# BlueNRG_LP register map
File version: 1.0
CPU: CM0+ r0p0, little endian, no MPU, no FPU, 2 interrupt priority bits
Registers are 32-bit, read-write, reset 0x0 unless marked. A register's access mark holds for its fields unless they carry their own. Offsets are from the block's base; [hi:lo] are bit positions; {n}, {i} and the like mark numbered series; 'fields as' and 'values as' point back to an identical list.

## RRM — Wakeup block version register
Base 0x60001400
0x00 RRM_ID ro
  [3:0] IDENTIFICATION
? AGC_HW_TRIM_OUT
  [3:1] HW_AGC_ANTENNAE_TRIM — AGC trim value (provided by the HW trimming, automatically loaded on POR).
0x04 RRM_CTRL
  [1:0] PRIORITY
0x08 RRM_TEST
0x10 UDRA_CTRL0
  [0] RELOAD_RDCFGPTR
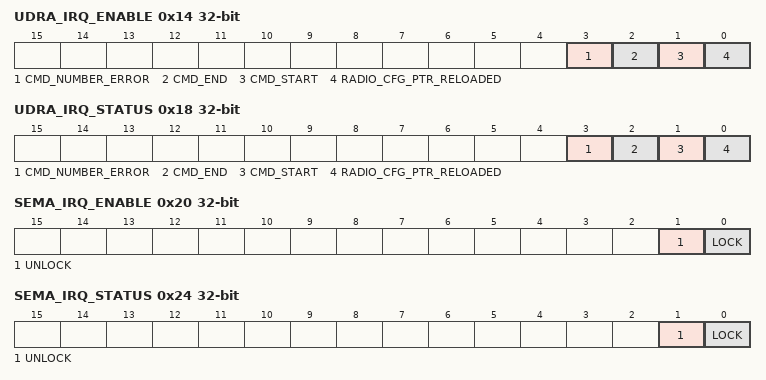
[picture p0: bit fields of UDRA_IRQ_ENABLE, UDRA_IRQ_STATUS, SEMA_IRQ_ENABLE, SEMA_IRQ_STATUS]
0x14 UDRA_IRQ_ENABLE
  [3] CMD_NUMBER_ERROR, [2] CMD_END, [1] CMD_START, [0] RADIO_CFG_PTR_RELOADED
0x18 UDRA_IRQ_STATUS
  fields as UDRA_IRQ_ENABLE
0x1C UDRA_RADIO_CFG_PTR ro
  [31:0] RADIO_CONFIG_ADDRESS
0x20 SEMA_IRQ_ENABLE
  [1] UNLOCK, [0] LOCK
0x24 SEMA_IRQ_STATUS ro
  [1] UNLOCK, [0] LOCK
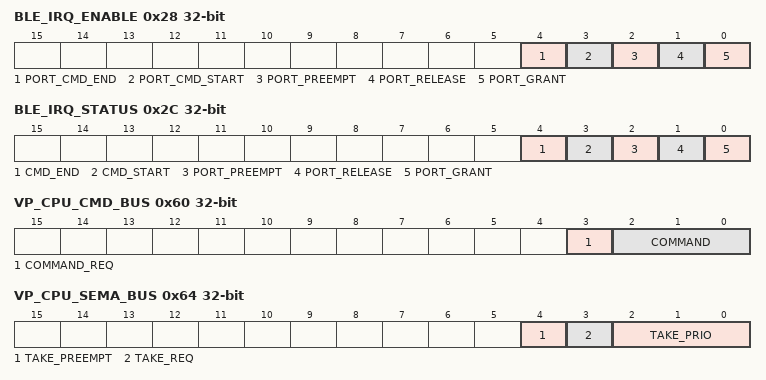
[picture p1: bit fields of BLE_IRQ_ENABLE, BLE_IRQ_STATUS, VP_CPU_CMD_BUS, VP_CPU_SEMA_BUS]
0x28 BLE_IRQ_ENABLE
  [4] PORT_CMD_END, [3] PORT_CMD_START, [2] PORT_PREEMPT, [1] PORT_RELEASE, [0] PORT_GRANT
0x2C BLE_IRQ_STATUS
  [4] CMD_END, [3] CMD_START, [2] PORT_PREEMPT, [1] PORT_RELEASE, [0] PORT_GRANT
0x60 VP_CPU_CMD_BUS
  [3] COMMAND_REQ, [2:0] COMMAND
0x64 VP_CPU_SEMA_BUS
  [4] TAKE_PREEMPT, [3] TAKE_REQ, [2:0] TAKE_PRIO
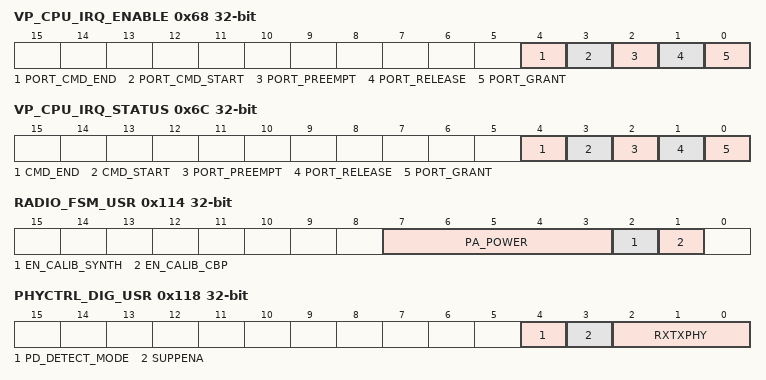
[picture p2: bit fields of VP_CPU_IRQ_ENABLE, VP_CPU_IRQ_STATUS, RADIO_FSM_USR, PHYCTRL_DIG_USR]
0x68 VP_CPU_IRQ_ENABLE
  fields as BLE_IRQ_ENABLE
0x6C VP_CPU_IRQ_STATUS
  fields as BLE_IRQ_STATUS
0x80 RRM_SPARE
{0x100+4i} AA{i}_DIG_USR (i=0..3)
  [7:0] AA_{8i+7}_{8i}
0x110 DEM_MOD_DIG_USR
  [7:1] CHANNEL_NUM
0x114 RADIO_FSM_USR
  [7:3] PA_POWER, [2] EN_CALIB_SYNTH, [1] EN_CALIB_CBP
0x118 PHYCTRL_DIG_USR
  [4] PD_DETECT_MODE, [3] SUPPENA, [2:0] RXTXPHY
{0x118+4i} PA_CODE{i}_DIG_ENG (i=1..7)
  [7:0] PA_CODE_{i}
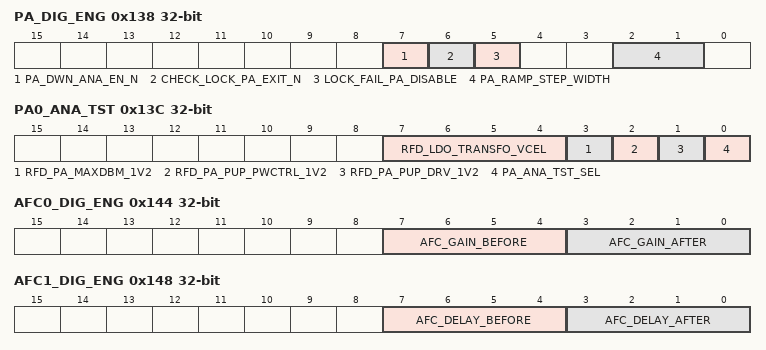
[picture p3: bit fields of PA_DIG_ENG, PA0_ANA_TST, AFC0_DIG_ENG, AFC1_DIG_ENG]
0x138 PA_DIG_ENG
  [7] PA_DWN_ANA_EN_N, [6] CHECK_LOCK_PA_EXIT_N, [5] LOCK_FAIL_PA_DISABLE, [2:1] PA_RAMP_STEP_WIDTH
0x13C PA0_ANA_TST
  [7:4] RFD_LDO_TRANSFO_VCEL, [3] RFD_PA_MAXDBM_1V2, [2] RFD_PA_PUP_PWCTRL_1V2, [1] RFD_PA_PUP_DRV_1V2, [0] PA_ANA_TST_SEL
0x140 PA1_ANA_TST
  [7:0] PA_CODE
0x144 AFC0_DIG_ENG
  [7:4] AFC_GAIN_BEFORE, [3:0] AFC_GAIN_AFTER
0x148 AFC1_DIG_ENG
  [7:4] AFC_DELAY_BEFORE, [3:0] AFC_DELAY_AFTER
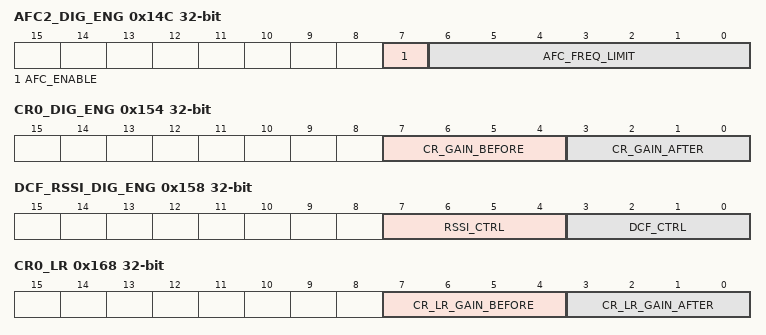
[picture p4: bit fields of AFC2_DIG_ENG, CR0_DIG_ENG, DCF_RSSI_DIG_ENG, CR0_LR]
0x14C AFC2_DIG_ENG
  [7] AFC_ENABLE, [6:0] AFC_FREQ_LIMIT
0x150 AFC3_DIG_ENG
  [7:0] AFC_MINMAX_LIMIT
0x154 CR0_DIG_ENG
  [7:4] CR_GAIN_BEFORE, [3:0] CR_GAIN_AFTER
0x158 DCF_RSSI_DIG_ENG
  [7:4] RSSI_CTRL, [3:0] DCF_CTRL
0x15C AAC0_DIG_ENG
  [7:0] AAC0_DIG_ENG_SPI
0x160 AAC1_DIG_ENG
  [7:0] AAC1_DIG_ENG_SPI
0x164 DEMOD_DIG_TST
  [7:1] TST_DUT
0x168 CR0_LR
  [7:4] CR_LR_GAIN_BEFORE, [3:0] CR_LR_GAIN_AFTER
0x16C VIT_CONF_DIG_ENG
  [7:0] VIT_CONF
{0x170+4i} VIT_METR{i}_DIG_ENG (i=0..3)
  [7:0] VIT_METR{i}
0x180 LR_RSSI_K_DIG_ENG
  [7:0] LR_RSSI_K
0x184 LR_PD_THR_DIG_ENG
  [7:0] LR_PD_THR
0x188 LR_RSSI_THR_DIG_ENG
  [7:0] LR_RSSI_THR
0x18C LR_AAC_THR_DIG_ENG
  [7:0] LR_AAC_THR
0x190 LR_PD_TIMEOUT_DIG_ENG
  [7:0] LR_PD_TIMEOUT
0x194 LR_AAC_TIMEOUT_DIG_ENG
  [7:0] LR_AAC_TIMEOUT
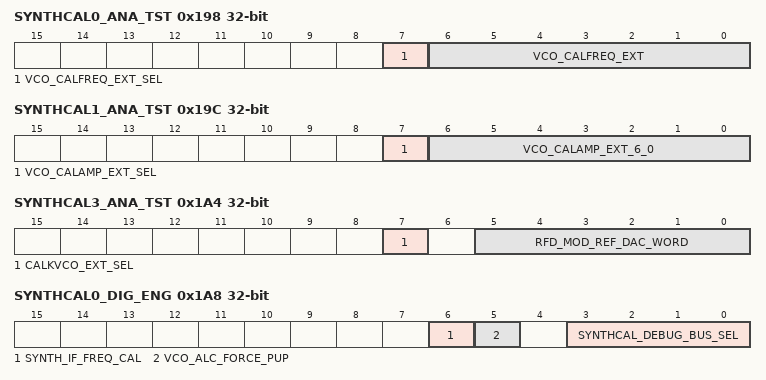
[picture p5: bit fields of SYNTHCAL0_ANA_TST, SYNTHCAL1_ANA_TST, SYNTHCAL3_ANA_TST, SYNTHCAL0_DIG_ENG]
0x198 SYNTHCAL0_ANA_TST
  [7] VCO_CALFREQ_EXT_SEL, [6:0] VCO_CALFREQ_EXT
0x19C SYNTHCAL1_ANA_TST
  [7] VCO_CALAMP_EXT_SEL, [6:0] VCO_CALAMP_EXT_6_0
0x1A0 SYNTHCAL2_ANA_TST
  [3:0] VCO_CALAMP_EXT_10_7
0x1A4 SYNTHCAL3_ANA_TST
  [7] CALKVCO_EXT_SEL, [5:0] RFD_MOD_REF_DAC_WORD
0x1A8 SYNTHCAL0_DIG_ENG
  [6] SYNTH_IF_FREQ_CAL, [5] VCO_ALC_FORCE_PUP, [3:0] SYNTHCAL_DEBUG_BUS_SEL
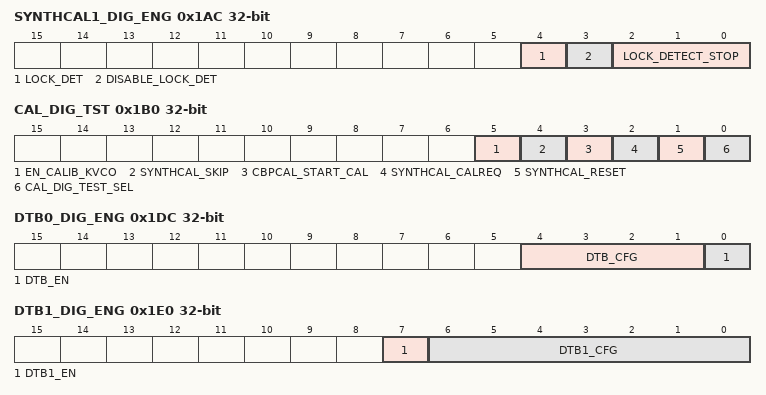
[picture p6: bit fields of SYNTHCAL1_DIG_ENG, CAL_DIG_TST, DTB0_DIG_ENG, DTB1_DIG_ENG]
0x1AC SYNTHCAL1_DIG_ENG
  [4] LOCK_DET, [3] DISABLE_LOCK_DET, [2:0] LOCK_DETECT_STOP
0x1B0 CAL_DIG_TST
  [5] EN_CALIB_KVCO, [4] SYNTHCAL_SKIP, [3] CBPCAL_START_CAL, [2] SYNTHCAL_CALREQ, [1] SYNTHCAL_RESET, [0] CAL_DIG_TEST_SEL
0x1B4 SYNTHCAL2_DIG_ENG
  [7:0] RFSYNTH_RFCOUNTER_7_0
0x1B8 FSM0_DIG_ENG
  [7:0] RX_TIMER
0x1BC FSM1_DIG_ENG
  [7:0] LDO_SHORT_TIMER
0x1C0 FSM2_DIG_ENG
  [7:0] LDO_TIMER
0x1C4 FSM3_DIG_ENG
  [7:0] LOCK_TIMEOUT
0x1C8 FSM4_DIG_ENG
  [7:0] CBPCAL_TIMEOUT
0x1CC FSM5_DIG_ENG
  [7:0] SYNTHCAL_TIMEOUT
0x1D0 FSM6_DIG_ENG
  [7:0] ENA_CURR_TIMEOUT
0x1D4 FSM7_DIG_ENG
  [7:0] VBG_BOOST_TIMEOUT
0x1D8 FSM8_DIG_ENG
  [7:0] PA_DWN_ANA_TIMEOUT
0x1DC DTB0_DIG_ENG
  [4:1] DTB_CFG, [0] DTB_EN
0x1E0 DTB1_DIG_ENG
  [7] DTB1_EN, [6:0] DTB1_CFG
0x1E4 DTB2_DIG_ENG
  [7:0] DTB2_CFG
0x1E8 DTB3_DIG_ENG
  [7:0] DTB3_CFG
0x1EC DTB4_DIG_ENG
  [2:0] DTB4_CFG
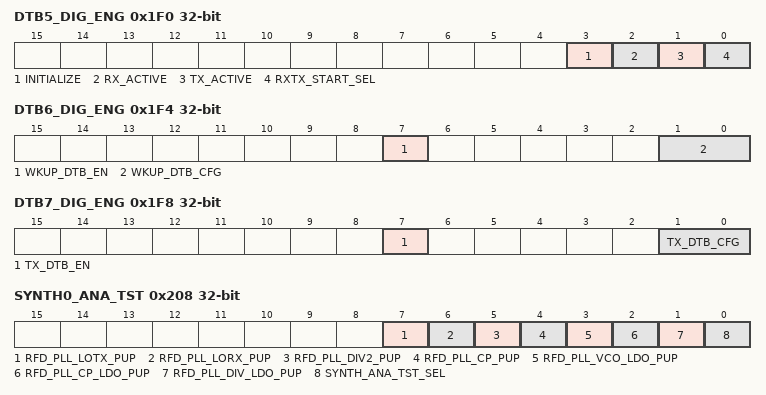
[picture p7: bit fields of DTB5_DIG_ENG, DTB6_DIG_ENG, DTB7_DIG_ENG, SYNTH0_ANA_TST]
0x1F0 DTB5_DIG_ENG
  [3] INITIALIZE, [2] RX_ACTIVE, [1] TX_ACTIVE, [0] RXTX_START_SEL
0x1F4 DTB6_DIG_ENG
  [7] WKUP_DTB_EN, [1:0] WKUP_DTB_CFG
0x1F8 DTB7_DIG_ENG
  [7] TX_DTB_EN, [1:0] TX_DTB_CFG
0x1FC DTB8_DIG_ENG
  [7:0] DTB8_CFG
0x200 DTB9_DIG_ENG
  [7:0] DTB9_CFG
0x204 DTBA_DIG_ENG
  [7:0] DTBA_CFG
0x208 SYNTH0_ANA_TST
  [7] RFD_PLL_LOTX_PUP, [6] RFD_PLL_LORX_PUP, [5] RFD_PLL_DIV2_PUP, [4] RFD_PLL_CP_PUP, [3] RFD_PLL_VCO_LDO_PUP, [2] RFD_PLL_CP_LDO_PUP, [1] RFD_PLL_DIV_LDO_PUP, [0] SYNTH_ANA_TST_SEL
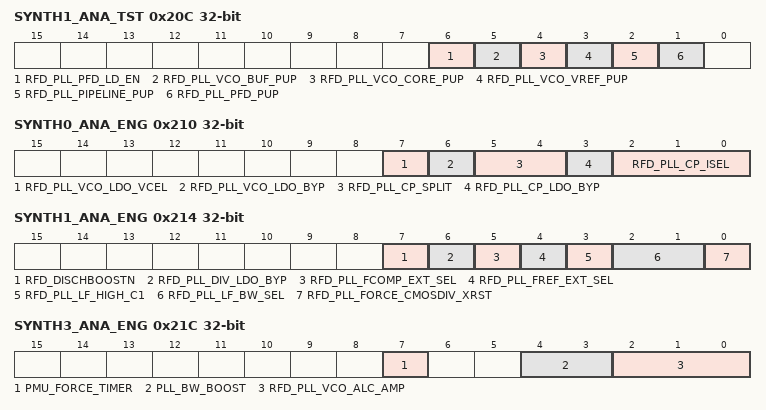
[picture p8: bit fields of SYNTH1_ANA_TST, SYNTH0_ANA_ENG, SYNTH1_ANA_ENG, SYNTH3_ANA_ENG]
0x20C SYNTH1_ANA_TST
  [6] RFD_PLL_PFD_LD_EN, [5] RFD_PLL_VCO_BUF_PUP, [4] RFD_PLL_VCO_CORE_PUP, [3] RFD_PLL_VCO_VREF_PUP, [2] RFD_PLL_PIPELINE_PUP, [1] RFD_PLL_PFD_PUP
0x210 SYNTH0_ANA_ENG
  [7] RFD_PLL_VCO_LDO_VCEL, [6] RFD_PLL_VCO_LDO_BYP, [5:4] RFD_PLL_CP_SPLIT, [3] RFD_PLL_CP_LDO_BYP, [2:0] RFD_PLL_CP_ISEL
0x214 SYNTH1_ANA_ENG
  [7] RFD_DISCHBOOSTN, [6] RFD_PLL_DIV_LDO_BYP, [5] RFD_PLL_FCOMP_EXT_SEL, [4] RFD_PLL_FREF_EXT_SEL, [3] RFD_PLL_LF_HIGH_C1, [2:1] RFD_PLL_LF_BW_SEL, [0] RFD_PLL_FORCE_CMOSDIV_XRST
0x218 SYNTH2_ANA_ENG
0x21C SYNTH3_ANA_ENG
  [7] PMU_FORCE_TIMER, [4:3] PLL_BW_BOOST, [2:0] RFD_PLL_VCO_ALC_AMP
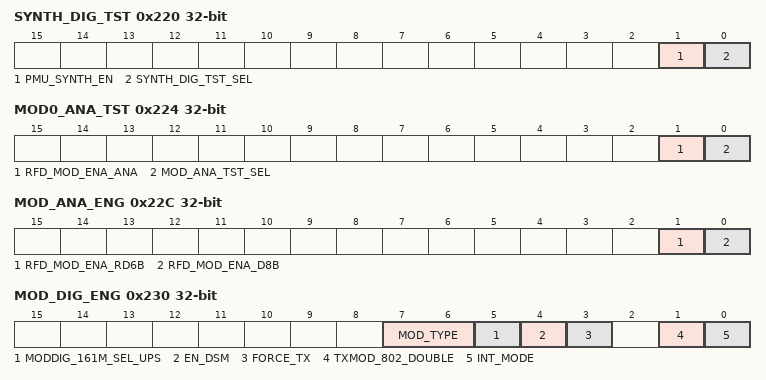
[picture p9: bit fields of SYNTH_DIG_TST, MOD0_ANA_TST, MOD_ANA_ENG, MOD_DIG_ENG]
0x220 SYNTH_DIG_TST
  [1] PMU_SYNTH_EN, [0] SYNTH_DIG_TST_SEL
0x224 MOD0_ANA_TST
  [1] RFD_MOD_ENA_ANA, [0] MOD_ANA_TST_SEL
0x228 MOD1_ANA_TST
  [7:0] TX_MOD_CALDAC
0x22C MOD_ANA_ENG
  [1] RFD_MOD_ENA_RD6B, [0] RFD_MOD_ENA_D8B
0x230 MOD_DIG_ENG
  [7:6] MOD_TYPE, [5] MODDIG_161M_SEL_UPS, [4] EN_DSM, [3] FORCE_TX, [1] TXMOD_802_DOUBLE, [0] INT_MODE
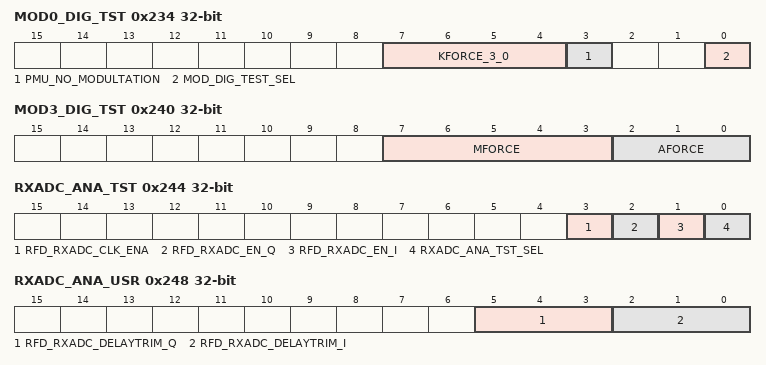
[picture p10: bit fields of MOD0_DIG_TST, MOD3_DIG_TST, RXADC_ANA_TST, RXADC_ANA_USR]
0x234 MOD0_DIG_TST
  [7:4] KFORCE_3_0, [3] PMU_NO_MODULTATION, [0] MOD_DIG_TEST_SEL
0x238 MOD1_DIG_TST
  [7:0] KFORCE_11_4
0x23C MOD2_DIG_TST
  [7:0] KFORCE_19_12
0x240 MOD3_DIG_TST
  [7:3] MFORCE, [2:0] AFORCE
0x244 RXADC_ANA_TST
  [3] RFD_RXADC_CLK_ENA, [2] RFD_RXADC_EN_Q, [1] RFD_RXADC_EN_I, [0] RXADC_ANA_TST_SEL
0x248 RXADC_ANA_USR
  [5:3] RFD_RXADC_DELAYTRIM_Q, [2:0] RFD_RXADC_DELAYTRIM_I
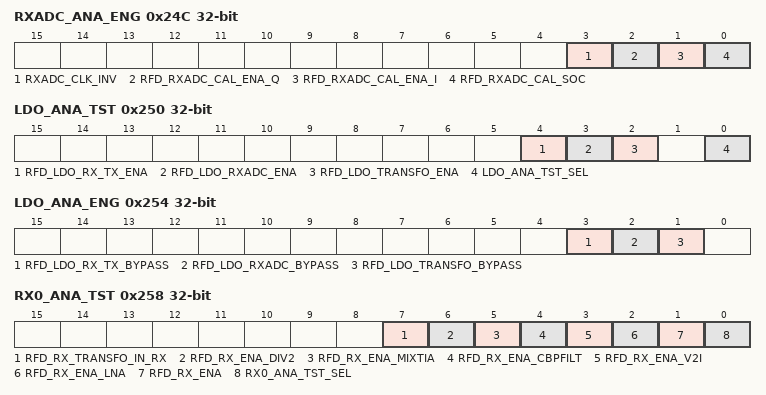
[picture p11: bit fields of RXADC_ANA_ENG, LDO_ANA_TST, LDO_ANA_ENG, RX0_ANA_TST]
0x24C RXADC_ANA_ENG
  [3] RXADC_CLK_INV, [2] RFD_RXADC_CAL_ENA_Q, [1] RFD_RXADC_CAL_ENA_I, [0] RFD_RXADC_CAL_SOC
0x250 LDO_ANA_TST
  [4] RFD_LDO_RX_TX_ENA, [3] RFD_LDO_RXADC_ENA, [2] RFD_LDO_TRANSFO_ENA, [0] LDO_ANA_TST_SEL
0x254 LDO_ANA_ENG
  [3] RFD_LDO_RX_TX_BYPASS, [2] RFD_LDO_RXADC_BYPASS, [1] RFD_LDO_TRANSFO_BYPASS
0x258 RX0_ANA_TST
  [7] RFD_RX_TRANSFO_IN_RX, [6] RFD_RX_ENA_DIV2, [5] RFD_RX_ENA_MIXTIA, [4] RFD_RX_ENA_CBPFILT, [3] RFD_RX_ENA_V2I, [2] RFD_RX_ENA_LNA, [1] RFD_RX_ENA, [0] RX0_ANA_TST_SEL
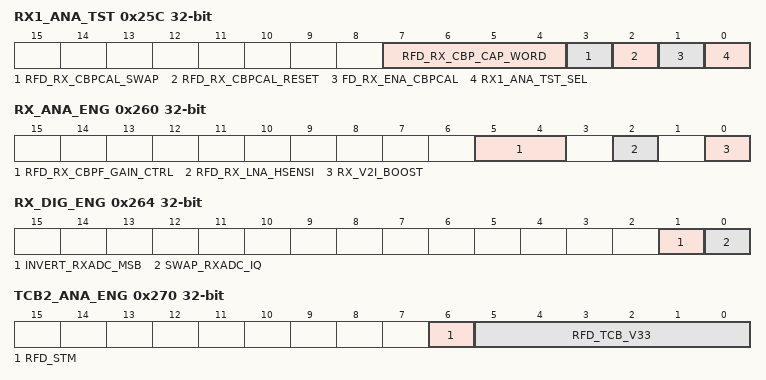
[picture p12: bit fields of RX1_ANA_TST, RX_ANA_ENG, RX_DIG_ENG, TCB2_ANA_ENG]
0x25C RX1_ANA_TST
  [7:4] RFD_RX_CBP_CAP_WORD, [3] RFD_RX_CBPCAL_SWAP, [2] RFD_RX_CBPCAL_RESET, [1] FD_RX_ENA_CBPCAL, [0] RX1_ANA_TST_SEL
0x260 RX_ANA_ENG
  [5:4] RFD_RX_CBPF_GAIN_CTRL, [2] RFD_RX_LNA_HSENSI, [0] RX_V2I_BOOST
0x264 RX_DIG_ENG
  [1] INVERT_RXADC_MSB, [0] SWAP_RXADC_IQ
0x268 TCB0_ANA_ENG
  [7:0] RFD_TCB_7_0
0x26C TCB1_ANA_ENG
  [0] RFD_TCB_8
0x270 TCB2_ANA_ENG
  [6] RFD_STM, [5:0] RFD_TCB_V33
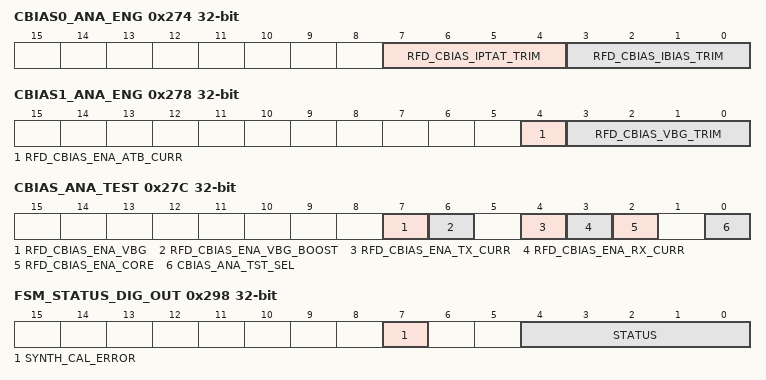
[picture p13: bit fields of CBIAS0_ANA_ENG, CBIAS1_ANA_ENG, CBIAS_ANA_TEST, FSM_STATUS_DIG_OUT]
0x274 CBIAS0_ANA_ENG
  [7:4] RFD_CBIAS_IPTAT_TRIM, [3:0] RFD_CBIAS_IBIAS_TRIM
0x278 CBIAS1_ANA_ENG
  [4] RFD_CBIAS_ENA_ATB_CURR, [3:0] RFD_CBIAS_VBG_TRIM
0x27C CBIAS_ANA_TEST
  [7] RFD_CBIAS_ENA_VBG, [6] RFD_CBIAS_ENA_VBG_BOOST, [4] RFD_CBIAS_ENA_TX_CURR, [3] RFD_CBIAS_ENA_RX_CURR, [2] RFD_CBIAS_ENA_CORE, [0] CBIAS_ANA_TST_SEL
0x280 SYNTHCAL0_DIG_OUT ro
  [6:0] VCO_CALAMP_OUT_6_0
0x284 SYNTHCAL1_DIG_OUT ro
  [3:0] VCO_CALAMP_OUT_10_7
0x288 SYNTHCAL2_DIG_OUT ro
  [6:0] VCO_CALFREQ_OUT
0x28C SYNTHCAL3_DIG_OUT ro
  [3:0] SYNTHCAL_DEBUG_BUS
0x290 SYNTHCAL4_DIG_OUT ro
  [5:0] MOD_REF_DAC_WORD_OUT
0x294 SYNTHCAL5_DIG_OUT ro
  [3:0] CBP_CALIB_WORD
0x298 FSM_STATUS_DIG_OUT ro
  [7] SYNTH_CAL_ERROR, [4:0] STATUS
0x29C IRQ_STATUS_DIG_OUT ro
0x2A0 SPARE_ANA_OUT ro
0x2A4 RSSI0_DIG_OUT ro
  [7:0] RSSI_MEAS_OUT_7_0
0x2A8 RSSI1_DIG_OUT ro
  [7:0] RSSI_MEAS_OUT_15_8
0x2AC AGC_DIG_OUT ro
  [3:0] AGC_ATT_OUT
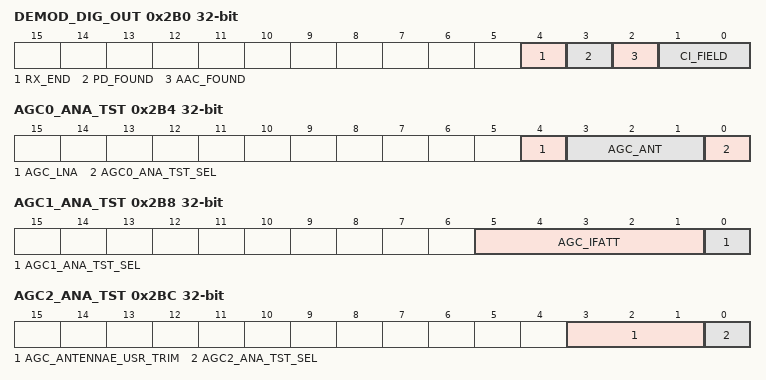
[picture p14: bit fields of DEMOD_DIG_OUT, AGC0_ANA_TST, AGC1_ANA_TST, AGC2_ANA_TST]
0x2B0 DEMOD_DIG_OUT ro
  [4] RX_END, [3] PD_FOUND, [2] AAC_FOUND, [1:0] CI_FIELD
0x2B4 AGC0_ANA_TST
  [4] AGC_LNA, [3:1] AGC_ANT, [0] AGC0_ANA_TST_SEL
0x2B8 AGC1_ANA_TST
  [5:1] AGC_IFATT, [0] AGC1_ANA_TST_SEL
0x2BC AGC2_ANA_TST
  [3:1] AGC_ANTENNAE_USR_TRIM, [0] AGC2_ANA_TST_SEL
0x2C0 AGC0_DIG_ENG
  [6] AGC_ENABLE, [5:0] AGC_THR_HIGH
0x2C4 AGC1_DIG_ENG
  [7] AGC_LOCK_SYNC, [6] AGC_AUTOLOCK, [5:0] AGC_THR_LOW_6
0x2C8 AGC2_DIG_ENG
  [5:0] AGC_THR_LOW_12
0x2CC AGC3_DIG_ENG
  [5:0] AUTOLOCK_THR
0x2D0 AGC4_DIG_ENG
  [7:4] AGC_HOLD_TIME_SLOW, [3:0] AGC_HOLD_TIME_FAST
0x2D4 AGC5_DIG_ENG
  [7:4] T_INT, [3:0] T_MEAS
0x2D8 AGC6_DIG_ENG
  [6:0] HOLD_TIME_SEL_10_4
0x2DC AGC7_DIG_ENG
  [6:0] TH_LOW_SEL_10_4
0x2E0 AGC8_DIG_ENG
  [7:4] TH_LOW_SEL_3_0, [3:0] HOLD_TIME_SEL_3_0
0x2E4 AGC9_DIG_ENG
  [7:4] MAX_SEQ, [3:0] START_SEQ
{0x2C0+4i} AGC{i}_DIG_ENG (i=10..19)
  [5:0] ATT_{i-10}
0x310 AGC20_DIG_ENG
  [7:0] I_GAIN_COMP
0x314 SPARE_ANA_IN_ENG
0x318 RF_ANA_ENG
  [2] FORCE_XO_READY, [1] RESETN_ATB, [0] HSE2ON_TEST
0x31C XO32M_ANA_TST
  [1] RFD_XO32M_XTCTRLPLL, [0] XO32M_TST_SEL
0x320 SPARE_DIG_USR
0x324 RXADC_HW_TRIM_OUT reset 0x1B
  [7:6] SPARE
  [5:3] HW_RXADC_DELAYTRIM_Q — control bits of the RX ADC loop delay for Q channel (provided by the HW trimming, automatically loaded on POR).
  [1:0] HW_RXADC_DELAYTRIM_I — control bits of the RX ADC loop delay for I channel (provided by the HW trimming, automatically loaded on POR).
0x328 CBIAS0_HW_TRIM_OUT reset 0x78
  [7:4] HW_CBIAS_IPTAT_TRIM — IPTAT current (provided by the HW trimming, automatically loaded on POR).
  [3:0] HW_CBIAS_IBIAS_TRIM — IPTAT current (provided by the HW trimming, automatically loaded on POR).
0x32C CBIAS1_HW_TRIM_OUT reset 0x8
  [2:0] HW_CBIAS_VBG_TRIM — VBG current (provided by the HW trimming, automatically loaded on POR).
